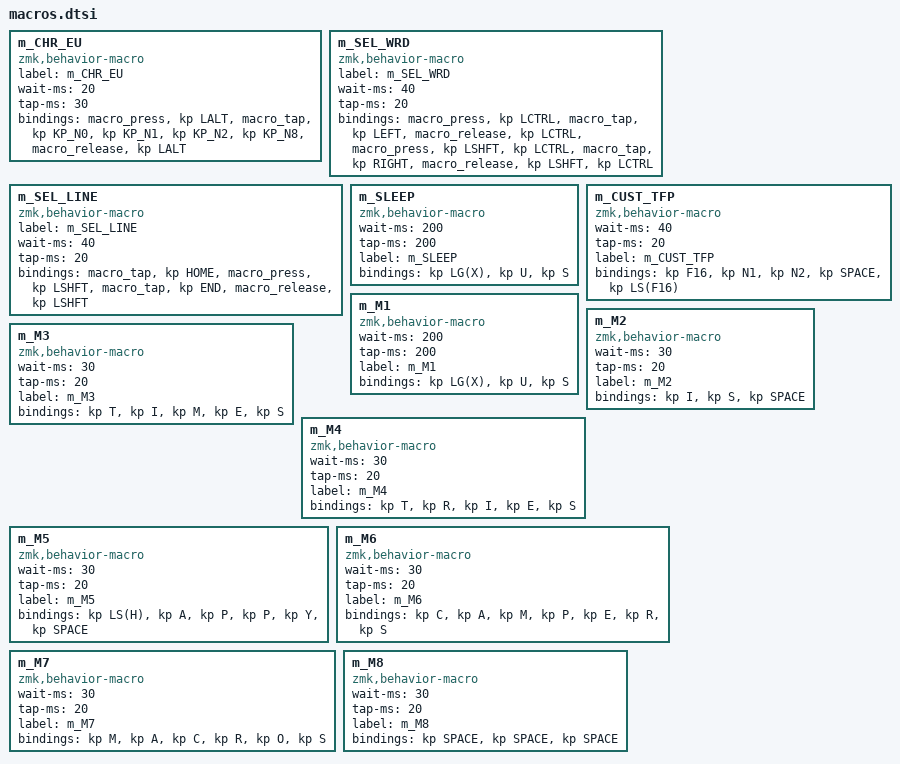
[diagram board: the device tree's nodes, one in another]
/* € - but clunky; seems some newer macros send Unicode better - need to search */
#include <dt-bindings/zmk/keys.h>
m_CHR_EU: m_CHR_EU{
    compatible = "zmk,behavior-macro";
    label = "m_CHR_EU";
    wait-ms = <20>;
    tap-ms = <30>;
    #binding-cells = <0>;
    bindings
        = <&macro_press   &kp LALT>
        , <&macro_tap     &kp KP_N0 &kp KP_N1 &kp KP_N2 &kp KP_N8>
        , <&macro_release &kp LALT>
        ;
};

/* SELECT WORD: Ctrl+LEFT, Ctrl+Shift+RIGHT */
m_SEL_WRD: m_SEL_WRD{
    compatible = "zmk,behavior-macro";
    label = "m_SEL_WRD";
    wait-ms = <40>;  /* 40,40 seems more reliable than 30,20 or faster */
    tap-ms = <20>;
    #binding-cells = <0>;
    bindings
        = <&macro_press &kp LCTRL>
        , <&macro_tap &kp LEFT>
        , <&macro_release &kp LCTRL>
        , <&macro_press &kp LSHFT &kp LCTRL>
        , <&macro_tap &kp RIGHT>
        , <&macro_release &kp LSHFT &kp LCTRL>
        ;
};

/* SELECT LINE: Home, Shift+End */
m_SEL_LINE: m_SEL_LINE{
    compatible = "zmk,behavior-macro";
    label = "m_SEL_LINE";
    wait-ms = <40>;
    tap-ms = <20>;
    #binding-cells = <0>;
    bindings
        = <&macro_tap &kp HOME>
        , <&macro_press &kp LSHFT>
        , <&macro_tap &kp END>
        , <&macro_release &kp LSHFT>
        ;
};

/* WINDOWS SLEEP: Win+X, U, S    (because the k-sleep and c-sleep don't seem to work / see https://github.com/zmkfirmware/zmk/issues/1077) */
/* NOT working yet; maybe need more pausing or split the sends?? */
m_SLEEP: m_SLEEP {
    wait-ms = <200>;
    tap-ms = <200>;  /* trying longer */
    compatible = "zmk,behavior-macro";
    label = "m_SLEEP";
    #binding-cells = <0>;
    bindings = <&kp LG(X)>, <&kp U>, <&kp S>; /* try separated? */
};

/* CUST_TFP - certain keystrokes to automate that one app hard function */
m_CUST_TFP: m_CUST_TFP {
    wait-ms = <40>;
    tap-ms = <20>;
    compatible = "zmk,behavior-macro";
    label = "m_CUST_TFP";
    #binding-cells = <0>;
    bindings = <&kp F16>, <&kp N1>, <&kp N2>, <&kp SPACE>, <&kp LS(F16)>;
};


/* simple F11 send works fine... A simple send F16 seems to do nothing... Is it the ≥F12 cases that's the issue? */
/* related to this option? https://github.com/zmkfirmware/zmk/issues/1460 ... ?  commented out this in 2 files (left, right): CONFIG_ZMK_HID_REPORT_TYPE_NKRO=y */
/* ******** YES YES ^^ commenting out this option then worked!  ********** */
/*
m_TestF11: m_TestF11 {
    wait-ms = <100>;
    tap-ms = <100>;
    compatible = "zmk,behavior-macro";
    label = "m_TestF11";
    #binding-cells = <0>;
    bindings = <&kp F11>;
};
*/

/* ************************************************** */
/* TEST macros to futz with settings in batches and string helpers
    tries with Shift and with Punctuation and spaces...
    [ ] does separating keys matter?
*/

/* TEMP comment out parts troubleshooting */
/*
m_M1: m_M1 {
    wait-ms = <30>;
    tap-ms = <20>;
    compatible = "zmk,behavior-macro";
    label = "m_M1";
    #binding-cells = <0>;
    bindings = <&kp LS(T)>, <&kp H>, <&kp I>, <&kp S>, <&kp SPACE>;
};
*/

/* TEMP try with dup of a prior one that worked */
/* did NOT work -- seems something around comments or gaps??? */
m_M1: m_M1 {
    wait-ms = <200>;
    tap-ms = <200>; 
    compatible = "zmk,behavior-macro";
    label = "m_M1";
    #binding-cells = <0>;
    bindings = <&kp LG(X)>, <&kp U>, <&kp S>; /* try separated? */
};



m_M2: m_M2 {
    wait-ms = <30>;
    tap-ms = <20>;
    compatible = "zmk,behavior-macro";
    label = "m_M2";
    #binding-cells = <0>;
    bindings = <&kp I>, <&kp S>, <&kp SPACE>;
};

m_M3: m_M3 {
    wait-ms = <30>;
    tap-ms = <20>;
    compatible = "zmk,behavior-macro";
    label = "m_M3";
    #binding-cells = <0>;
    bindings = <&kp T &kp I &kp M &kp E &kp S>;
};

m_M4: m_M4 {
    wait-ms = <30>;
    tap-ms = <20>;
    compatible = "zmk,behavior-macro";
    label = "m_M4";
    #binding-cells = <0>;
    bindings = <&kp T &kp R &kp I &kp E &kp S>;
};

m_M5: m_M5 {
    wait-ms = <30>;
    tap-ms = <20>;
    compatible = "zmk,behavior-macro";
    label = "m_M5";
    #binding-cells = <0>;
    bindings = <&kp LS(H) &kp A &kp P &kp P &kp Y &kp SPACE>;
};

m_M6: m_M6 {
    wait-ms = <30>;
    tap-ms = <20>;
    compatible = "zmk,behavior-macro";
    label = "m_M6";
    #binding-cells = <0>;
    bindings = <&kp C &kp A &kp M &kp P &kp E &kp R &kp S>;
};

m_M7: m_M7 {
    wait-ms = <30>;
    tap-ms = <20>;
    compatible = "zmk,behavior-macro";
    label = "m_M7";
    #binding-cells = <0>;
    bindings = <&kp M &kp A &kp C &kp R &kp O &kp S>;
};

m_M8: m_M8 {
    wait-ms = <30>;
    tap-ms = <20>;
    compatible = "zmk,behavior-macro";
    label = "m_M8";
    #binding-cells = <0>;
    bindings = <&kp SPACE &kp SPACE &kp SPACE>;
};




/* ************************************************** */
/* see also EW Notes file */

/* ************************************************** */
/* try ZMK macro helper shortcut -- NOT WORKING with nested FN() calls -- come back to later? */
/*
ZMK_MACRO(m_TEST2
    wait-ms = <30>;
    tap-ms = <20>;
    bindings = <&kp A>, <&kp B>;
)
*/

